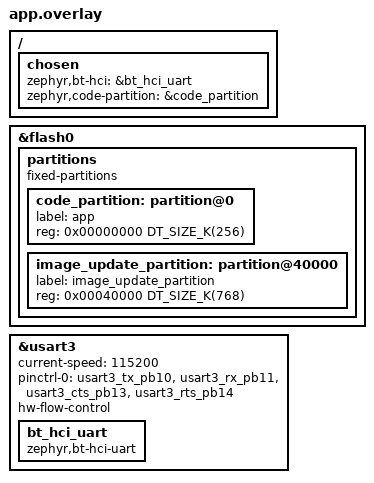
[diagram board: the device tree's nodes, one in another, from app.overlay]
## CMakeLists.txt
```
# SPDX-License-Identifier: Apache-2.0

cmake_minimum_required(VERSION 3.20.0)
set(BOARD stm32f4_disco)
find_package(Zephyr REQUIRED HINTS $ENV{ZEPHYR_BASE})
project(gateway)

include(${ZEPHYR_BASE}/samples/subsys/usb/common/common.cmake)
target_include_directories(app PRIVATE src/)
FILE(GLOB gateway_sources src/main.c 
                          src/command.c
                          src/external_firmware_update.c
                          
)
target_sources(app PRIVATE ${gateway_sources})
```

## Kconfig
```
# Copyright (c) 2023 Nordic Semiconductor ASA
# SPDX-License-Identifier: Apache-2.0

# Source common USB sample options used to initialize new experimental USB
# device stack. The scope of these options is limited to USB samples in project
# tree, you cannot use them in your own application.
# source "samples/subsys/usb/common/Kconfig.sample_usbd"

 source "Kconfig.zephyr"
```

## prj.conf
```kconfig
# enables the new gen usb stack
# CONFIG_USB_DEVICE_STACK_NEXT=y

# enables the console subsystem where the stdout will be redirected
CONFIG_STDOUT_CONSOLE=y

# enables serial/uart subsystem 
CONFIG_SERIAL=y

# for setting DTR, DSR, DCD, baud rate. uart_line_ctrl_get(dev, UART_LINE_CTRL_DTR, &dtr) which gives access to zephyr/drivers/uart.h
# important for 	k_msleep(100);
# CONFIG_UART_LINE_CTRL=y

# makes the cdc acm class instance not auto initialize (usbd_enable()), instead
# you do it manually in the code
# CONFIG_CDC_ACM_SERIAL_INITIALIZE_AT_BOOT=n

#enables log
CONFIG_LOG=y


CONFIG_LOG_MODE_IMMEDIATE=y

# limits log priority of usbd to err
# CONFIG_USBD_LOG_LEVEL_ERR=y

# Same idea, but for the UDC driver layer (the hardware controller driver itself) — errors only.
# CONFIG_UDC_DRIVER_LOG_LEVEL_ERR=y


# CONFIG_USBD_CDC_ACM_LOG_LEVEL_OFF=y
CONFIG_CONSOLE=y
CONFIG_UART_CONSOLE=y
CONFIG_WARN_EXPERIMENTAL=y
# CONFIG_SAMPLE_USBD_PID=0x0001
# CONFIG_SAMPLE_USBD_PRODUCT="USBD CDC ACM sample"

CONFIG_GPIO=y

# bluetooth hci uart setup
CONFIG_BT=y

# Directs Zephyr to route HCI packets over the physical UART peripheral 
# selected by your 'zephyr,bt-hci' chosen property in the device tree
# cna't configure it CONFIG_BT_UART=y


CONFIG_BT_H4=y

CONFIG_MAIN_STACK_SIZE=2048
CONFIG_SYSTEM_WORKQUEUE_STACK_SIZE=2048
CONFIG_BT_RX_STACK_SIZE=2048
# Allocates the background thread stack size for handling outgoing HCI packets
CONFIG_BT_HCI_TX_STACK_SIZE=1024



CONFIG_BT_HCI=y
CONFIG_BT_LL_SW_SPLIT=n #unsure
CONFIG_BT_DEVICE_NAME="gateway"

# central config
CONFIG_BT_CENTRAL=y
CONFIG_BT_SMP=y
CONFIG_BT_GATT_CLIENT=y
CONFIG_BT_HCI_ACL_FLOW_CONTROL=n

#CONFIG_BT_CTLR=n


CONFIG_UART_INTERRUPT_DRIVEN=y


CONFIG_FLASH_MAP=y
CONFIG_FLASH=y


CONFIG_BT_L2CAP_TX_MTU=247
CONFIG_BT_BUF_ACL_RX_SIZE=251
CONFIG_BT_GATT_CLIENT=y

#CONFIG_BT_CONN_TX_MAX=10
CONFIG_BT_BUF_ACL_TX_COUNT=10
CONFIG_BT_BUF_EVT_RX_COUNT=11
#CONFIG_BT_BUF_ACL_RX_COUNT_EXTRA=8
```

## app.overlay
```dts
/*
 * Copyright (c) 2021 Nordic Semiconductor ASA
 *
 * SPDX-License-Identifier: Apache-2.0
 */
/*
&zephyr_udc0 {
	cdc_acm_uart0: cdc_acm_uart0 {
		compatible = "zephyr,cdc-acm-uart";
		label = "Zephyr USB CDC-ACM";
	};
};
*/


// separating flash0 into partitions

&flash0 {
    partitions {
        compatible = "fixed-partitions";
        #address-cells = <1>;
        #size-cells = <1>;

        code_partition: partition@0 {
            label = "app";
            reg = <0x00000000 DT_SIZE_K(256)>;
        };

        image_update_partition: partition@40000 {
            label = "image_update_partition";
            reg = <0x00040000 DT_SIZE_K(768)>;
        };
    };
};





&usart3 {
    status = "okay";
    current-speed = <115200>;

    pinctrl-0 = <&usart3_tx_pb10 &usart3_rx_pb11 &usart3_cts_pb13 &usart3_rts_pb14>;
    pinctrl-names = "default";
	hw-flow-control;

    bt_hci_uart: bt_hci_uart {
        compatible = "zephyr,bt-hci-uart";
        status = "okay";
    };
};

/ {
    chosen {
        //zephyr,console = &cdc_acm_uart0;
//		zephyr,shell-uart= &cdc_acm_uart0;
		zephyr,bt-hci = &bt_hci_uart;
        zephyr,code-partition = &code_partition;

    };
};
```

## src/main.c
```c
/*
 * Copyright (c) 2019 Intel Corporation
 *
 * SPDX-License-Identifier: Apache-2.0
 */

#include <zephyr/types.h>
#include <stddef.h>
#include <errno.h>
#include <zephyr/kernel.h>
#include <zephyr/sys/printk.h>

#include <zephyr/bluetooth/bluetooth.h>
#include <zephyr/bluetooth/hci.h>
#include <zephyr/bluetooth/conn.h>
#include <zephyr/bluetooth/uuid.h>
#include <zephyr/bluetooth/gatt.h>
#include <zephyr/sys/byteorder.h>
#include <command.h>
#include <external_firmware_update.h>
// LOG_MODULE_REGISTER(main_log, LOG_LEVEL_INF);
static int start_scan(void);


#define DEVICE_NAME CONFIG_BT_DEVICE_NAME
#define DEVICE_NAME_LEN (sizeof(DEVICE_NAME) - 1)


/* Target service :*/
#define BT_UUID_CUSTOM_SERVICE_VAL \
	BT_UUID_128_ENCODE(0x12345678, 0x1234, 0x5678, 0x1234, 0x56789abcdef0)

static const struct bt_uuid_128 vnd_uuid = BT_UUID_INIT_128(
	BT_UUID_CUSTOM_SERVICE_VAL);

// sensor notification -------------------------------------------------------->
static const struct bt_uuid_128 vnd_sensor_uuid = BT_UUID_INIT_128(
BT_UUID_128_ENCODE(0x12345678, 0x1234, 0x5678, 0x1234, 0x56789abcdef5));




// message -------------------------------------------------------->
// message characteristic 
static const struct bt_uuid_128 vnd_msg_uuid = BT_UUID_INIT_128(
	BT_UUID_128_ENCODE(0x12345678, 0x1234, 0x5678, 0x1234, 0x56789abcdef6));

const struct bt_uuid_128 vnd_cmd_uuid = BT_UUID_INIT_128(
	BT_UUID_128_ENCODE(0x12345678, 0x1234, 0x5678, 0x1234, 0x56789abcdef7));

static const struct bt_uuid_128 vnd_cmd_feedback_uuid = BT_UUID_INIT_128(
BT_UUID_128_ENCODE(0x12345678, 0x1234, 0x5678, 0x1234, 0x56789abcdef8));

static const struct bt_uuid_128 vnd_payload_size_uuid = BT_UUID_INIT_128(
BT_UUID_128_ENCODE(0x12345678, 0x1234, 0x5678, 0x1234, 0x56789abcdef9));


static const struct bt_uuid_128 vnd_payload_chunk_uuid = BT_UUID_INIT_128(
BT_UUID_128_ENCODE(0x12345678, 0x1234, 0x5678, 0x1234, 0x56789abcdef10));

static const struct bt_uuid_128 vnd_payload_chunk_feedback_uuid = BT_UUID_INIT_128(
BT_UUID_128_ENCODE(0x12345678, 0x1234, 0x5678, 0x1234, 0x56789abcdef11));





#define MSG_MAX_LEN 32
char msg[MSG_MAX_LEN + 1] = {0};
uint16_t msg_attr_handle;
void msg_write_cb(struct bt_conn *conn, uint8_t err, struct bt_gatt_write_params *params){
	printf("a msg write request was sent!\n");
}
struct bt_gatt_write_params msg_write_params = {
	.func = msg_write_cb,
	.data = msg,
	.offset = 0,
	.length = MSG_MAX_LEN 
	
};
bool msg_ready = false;
// message -------------------------------------------------------->




struct bt_conn *default_conn;

uint64_t total_rx_count; /* This value is exposed to test code */
static struct bt_uuid_128 discover_uuid = BT_UUID_INIT_128(0);
static struct bt_gatt_discover_params discover_params;
static struct bt_gatt_subscribe_params subscribe_params;


static uint8_t notify_func(struct bt_conn *conn,
			   struct bt_gatt_subscribe_params *params,
			   const void *data, uint16_t length)
{
	if (!data) {
		printk("[UNSUBSCRIBED]\n");
		params->value_handle = 0U;
		return BT_GATT_ITER_STOP;
	}

	printk("[NOTIFICATION] data %p length %u\n", data, length);

	if (length == sizeof(int16_t)) {
		int16_t sensor_value;

		memcpy(&sensor_value, data, sizeof(sensor_value));
		sensor_value = sys_le16_to_cpu(sensor_value);

		printk("[NOTIFICATION] sensor value: %d\n", sensor_value);
	} else {
		printk("[NOTIFICATION] unexpected length %u\n", length);
	}
	total_rx_count++;

	return BT_GATT_ITER_CONTINUE;
}

enum subscribe_target {
    SUBSCRIBE_TARGET_NONE,
    SUBSCRIBE_TARGET_SENSOR,
    SUBSCRIBE_TARGET_CMD_FEEDBACK,
	SUBSCRIBE_TARGET_PAYLOAD_CHUNK_FEEDBACK,
};
static enum subscribe_target pending_subscribe_target = SUBSCRIBE_TARGET_NONE;

bool discovery_complete = false;
static uint8_t discover_func(struct bt_conn *conn,
			     const struct bt_gatt_attr *attr,
			     struct bt_gatt_discover_params *params)
{
	int err;

	if (!attr) {
		printk("Discover complete\n");
		(void)memset(params, 0, sizeof(*params));
		return BT_GATT_ITER_STOP;
	}

	printk("[ATTRIBUTE] handle %u\n", attr->handle);

	if (!bt_uuid_cmp(discover_params.uuid, &vnd_uuid.uuid)) {

		memcpy(&discover_uuid, &vnd_sensor_uuid, sizeof(discover_uuid));
		discover_params.uuid = &discover_uuid.uuid;
		discover_params.start_handle = attr->handle + 1;
		discover_params.type = BT_GATT_DISCOVER_CHARACTERISTIC;

		err = bt_gatt_discover(conn, &discover_params);
		if (err) {
			printk("Discover failed (err %d)\n", err);
		}

	} else if (!bt_uuid_cmp(discover_params.uuid,
				&vnd_msg_uuid.uuid)) {
		//memcpy(&discover_uuid, BT_UUID_GATT_CCC, sizeof(struct bt_uuid_16));
		//discover_params.uuid = &discover_uuid.uuid;
		//discover_params.start_handle = attr->handle + 2;
		//discover_params.type = BT_GATT_DISCOVER_DESCRIPTOR;

		msg_attr_handle = bt_gatt_attr_value_handle(attr);
		msg_write_params.handle = msg_attr_handle;
		msg_ready = true;


		// discover cmd
		memcpy(&discover_uuid, &vnd_cmd_uuid, sizeof(discover_uuid));
		discover_params.uuid = &discover_uuid.uuid;
		discover_params.start_handle = BT_ATT_FIRST_ATTRIBUTE_HANDLE;
		discover_params.type = BT_GATT_DISCOVER_CHARACTERISTIC;

		err = bt_gatt_discover(conn, &discover_params);
		if (err) {
			printk("Discover failed (err %d)\n", err);
		}
	 
		// cmd
	}  else if (!bt_uuid_cmp(discover_params.uuid,
				&vnd_cmd_uuid.uuid)) {

		 
		cmd_write_params.handle = bt_gatt_attr_value_handle(attr);
		
		// redirect to cmd_feedback
		memcpy(&discover_uuid, &vnd_cmd_feedback_uuid, sizeof(discover_uuid));
		discover_params.uuid = &discover_uuid.uuid;
		discover_params.start_handle = BT_ATT_FIRST_ATTRIBUTE_HANDLE;
		discover_params.type = BT_GATT_DISCOVER_CHARACTERISTIC;

		err = bt_gatt_discover(conn, &discover_params);
		if (err) {
			printk("Discover failed (err %d)\n", err);
		}

		// cmd_feedback
	}  else if (!bt_uuid_cmp(discover_params.uuid,
				&vnd_cmd_feedback_uuid.uuid)) {

		memcpy(&discover_uuid, BT_UUID_GATT_CCC, sizeof(struct bt_uuid_16));
		discover_params.uuid = &discover_uuid.uuid;
		discover_params.start_handle = attr->handle + 2;
		discover_params.type = BT_GATT_DISCOVER_DESCRIPTOR;
		cmd_feedback_subscribe_params.value_handle = bt_gatt_attr_value_handle(attr);

		pending_subscribe_target = SUBSCRIBE_TARGET_CMD_FEEDBACK;
		err = bt_gatt_discover(conn, &discover_params);
		if (err) {
			printk("Discover failed (err %d)\n", err);
		}
		// sensor
	}	else if (!bt_uuid_cmp(discover_params.uuid,
				&vnd_sensor_uuid.uuid)) {
		memcpy(&discover_uuid, BT_UUID_GATT_CCC, sizeof(struct bt_uuid_16));
		discover_params.uuid = &discover_uuid.uuid;
		discover_params.start_handle = attr->handle + 2;
		discover_params.type = BT_GATT_DISCOVER_DESCRIPTOR;
		subscribe_params.value_handle = bt_gatt_attr_value_handle(attr);

		pending_subscribe_target = SUBSCRIBE_TARGET_SENSOR; 
		err = bt_gatt_discover(conn, &discover_params);
		if (err) {
			printk("Discover failed (err %d)\n", err);
		}

	// discovering payloady_size
	}  else if (!bt_uuid_cmp(discover_params.uuid,
				&vnd_payload_size_uuid.uuid)) {

		 
			payload_size_write_params.handle = bt_gatt_attr_value_handle(attr);

			// redirecting to discover payload_chunk next
			memcpy(&discover_uuid, &vnd_payload_chunk_uuid, sizeof(discover_uuid));
			discover_params.uuid = &discover_uuid.uuid;
			discover_params.start_handle = BT_ATT_FIRST_ATTRIBUTE_HANDLE;
			discover_params.type = BT_GATT_DISCOVER_CHARACTERISTIC;

			err = bt_gatt_discover(conn, &discover_params);
			if (err) {
				printk("Discover failed (err %d)\n", err);

			}
		

	// discovering payloady_chunk
	}  else if (!bt_uuid_cmp(discover_params.uuid,
				&vnd_payload_chunk_uuid.uuid)) {

		 
		payload_chunk_write_params.handle = bt_gatt_attr_value_handle(attr);
		
		// redirect to payload_chunk_feedback 
		memcpy(&discover_uuid, &vnd_payload_chunk_feedback_uuid, sizeof(discover_uuid));
		discover_params.uuid = &discover_uuid.uuid;
		discover_params.start_handle = BT_ATT_FIRST_ATTRIBUTE_HANDLE;
		discover_params.type = BT_GATT_DISCOVER_CHARACTERISTIC;

		err = bt_gatt_discover(conn, &discover_params);
		if (err) {
			printk("Discover failed (err %d)\n", err);
		}

	// discovering payloady_chunk_feedback
	}  else if (!bt_uuid_cmp(discover_params.uuid,
				&vnd_payload_chunk_feedback_uuid.uuid)) {

		 
		
		memcpy(&discover_uuid, BT_UUID_GATT_CCC, sizeof(struct bt_uuid_16));
		discover_params.uuid = &discover_uuid.uuid;
		discover_params.start_handle = attr->handle + 2;
		discover_params.type = BT_GATT_DISCOVER_DESCRIPTOR;
		payload_chunk_feedback_subscribe_params.value_handle = bt_gatt_attr_value_handle(attr);

		pending_subscribe_target = SUBSCRIBE_TARGET_PAYLOAD_CHUNK_FEEDBACK;
		err = bt_gatt_discover(conn, &discover_params);
		if (err) {
			printk("Discover failed (err %d)\n", err);
		}
	} else //if 
	//(!bt_uuid_cmp(discover_params.uuid, BT_UUID_GATT_CCC.uuid)) 
	{
		if(pending_subscribe_target == SUBSCRIBE_TARGET_SENSOR){
			subscribe_params.notify = notify_func;
			subscribe_params.value = BT_GATT_CCC_NOTIFY;
			subscribe_params.ccc_handle = attr->handle;

			err = bt_gatt_subscribe(conn, &subscribe_params);
			if (err && err != -EALREADY) {
				printk("Subscribe failed (err %d)\n", err);
			} else {
				printk("[SUBSCRIBED] sensor notification\n");
			}

			memcpy(&discover_uuid, &vnd_msg_uuid, sizeof(discover_uuid));
			discover_params.uuid = &discover_uuid.uuid;
			discover_params.start_handle = BT_ATT_FIRST_ATTRIBUTE_HANDLE;
			discover_params.type = BT_GATT_DISCOVER_CHARACTERISTIC;

			err = bt_gatt_discover(conn, &discover_params);
			if (err) {
				printk("Discover failed (err %d)\n", err);

			}
		}
		else if(pending_subscribe_target == SUBSCRIBE_TARGET_CMD_FEEDBACK){
			cmd_feedback_subscribe_params.notify = cmd_feedback_notify_func;
			cmd_feedback_subscribe_params.value = BT_GATT_CCC_NOTIFY;
			cmd_feedback_subscribe_params.ccc_handle = attr->handle;

			err = bt_gatt_subscribe(conn, &cmd_feedback_subscribe_params);
			if (err && err != -EALREADY) {
				printk("Subscribe failed (err %d)\n", err);
			} else {
				printk("[SUBSCRIBED] to cmd feedback notification\n");
			}

			// redirecting to discover payloay_size next
			memcpy(&discover_uuid, &vnd_payload_size_uuid, sizeof(discover_uuid));
			discover_params.uuid = &discover_uuid.uuid;
			discover_params.start_handle = BT_ATT_FIRST_ATTRIBUTE_HANDLE;
			discover_params.type = BT_GATT_DISCOVER_CHARACTERISTIC;

			err = bt_gatt_discover(conn, &discover_params);
			if (err) {
				printk("Discover failed (err %d)\n", err);

			}

			
		}
		
		else if(pending_subscribe_target == SUBSCRIBE_TARGET_PAYLOAD_CHUNK_FEEDBACK){
			payload_chunk_feedback_subscribe_params.notify = payload_chunk_feedback_notify_func;
			payload_chunk_feedback_subscribe_params.value = BT_GATT_CCC_NOTIFY;
			payload_chunk_feedback_subscribe_params.ccc_handle = attr->handle;

			err = bt_gatt_subscribe(conn, &payload_chunk_feedback_subscribe_params);
			if (err && err != -EALREADY) {
				printk("Subscribe failed (err %d)\n", err);
			} else {
				printk("[SUBSCRIBED] to payload chunk feedback notification\n");
			}

			discovery_complete = true;
			
		}

	}

	return BT_GATT_ITER_STOP;
}

/*
static bool eir_found(struct bt_data *data, void *user_data)
{
	bt_addr_le_t *addr = user_data;
	int i;

	printk("[AD]: %u data_len %u\n", data->type, data->data_len);

	switch (data->type) {
	case BT_DATA_UUID128_SOME:
	case BT_DATA_UUID128_ALL:
		// check if we can fine a multiple of 16 bytes uuid (128 bits)
		if (data->data_len % 16 != 0U) {
			printk("AD malformed\n");
			return true;
		}

		for (i = 0; i < data->data_len; i += 16) {
			struct bt_conn_le_create_param *create_param;
			struct bt_le_conn_param *param;
			// const struct bt_uuid *uuid;
			// uint16_t u16;
			struct bt_uuid_128 uuid128;
			uuid128.uuid.type = BT_UUID_TYPE_128;
			int err;

			memcpy(&uuid128.val, &data->data[i], 16);
			// uuid = BT_UUID_DECLARE_16(sys_le16_to_cpu(u16));
			if (bt_uuid_cmp(&uuid128.uuid, &vnd_uuid.uuid)) {
				continue;
			}

			err = bt_le_scan_stop();
			if (err) {
				printk("Stop LE scan failed (err %d)\n", err);
				continue;
			}

			printk("Creating connection with Coded PHY support\n");
			param = BT_LE_CONN_PARAM_DEFAULT;
			create_param = BT_CONN_LE_CREATE_CONN;
			create_param->options |= BT_CONN_LE_OPT_CODED;
			err = bt_conn_le_create(addr, create_param, param,
						&default_conn);
			if (err) {
				printk("Create connection with Coded PHY support failed (err %d)\n",
				       err);

				printk("Creating non-Coded PHY connection\n");
				create_param->options &= ~BT_CONN_LE_OPT_CODED;
				err = bt_conn_le_create(addr, create_param,
							param, &default_conn);
				if (err) {
					printk("Create connection failed (err %d)\n", err);
					start_scan();
				}
			}

			return false;
		}
	}

	return true;
}
*/

static bool eir_found(struct bt_data *data, void *user_data)
{
    bt_addr_le_t *addr = user_data;
    int i;

    printk("[AD]: %u data_len %u\n", data->type, data->data_len);

    switch (data->type) {
    case BT_DATA_UUID128_SOME:
    case BT_DATA_UUID128_ALL:
        if (data->data_len % 16 != 0U) {
            printk("AD malformed\n");
            return true;
        }

        for (i = 0; i < data->data_len; i += 16) {
            struct bt_le_conn_param *param;
            struct bt_uuid_128 uuid128;
            uuid128.uuid.type = BT_UUID_TYPE_128;
            int err;

            memcpy(&uuid128.val, &data->data[i], 16);
            if (bt_uuid_cmp(&uuid128.uuid, &vnd_uuid.uuid)) {
                continue;
            }

            err = bt_le_scan_stop();
            if (err) {
                printk("Stop LE scan failed (err %d)\n", err);
                continue;
            }

            printk("Creating connection\n");
            param = BT_LE_CONN_PARAM_DEFAULT;
            err = bt_conn_le_create(addr, BT_CONN_LE_CREATE_CONN, param, &default_conn);
            if (err) {
                printk("Create connection failed (err %d)\n", err);
                start_scan();
            }

            return false;
        }
    }

    return true;
}

static void device_found(const bt_addr_le_t *addr, int8_t rssi, uint8_t type,
			 struct net_buf_simple *ad)
{
	printk("[DEVICE]: %s, AD evt type %u, AD data len %u, RSSI %i\n",
	       bt_addr_le_str(addr), type, ad->len, rssi);

	/* We're only interested in legacy connectable events or
	 * possible extended advertising that are connectable.
	 */
	if (type == BT_GAP_ADV_TYPE_ADV_IND ||
	    type == BT_GAP_ADV_TYPE_ADV_DIRECT_IND ||
	    type == BT_GAP_ADV_TYPE_EXT_ADV) {
		bt_data_parse(ad, eir_found, (void *)addr);
	}
}

static int start_scan(void)
{
	int err;

	/* Use active scanning and disable duplicate filtering to handle any
	 * devices that might update their advertising data at runtime. */
	struct bt_le_scan_param scan_param = {
		.type       = BT_LE_SCAN_TYPE_ACTIVE,
		.options    = BT_LE_SCAN_OPT_NONE,
		.interval   = BT_GAP_SCAN_FAST_INTERVAL,
		.window     = BT_GAP_SCAN_FAST_WINDOW,
	};

	err = bt_le_scan_start(&scan_param, device_found);
	if (err) {
		/*
		printk("Scanning with Coded PHY support failed (err %d)\n", err);

		printk("Scanning without Coded PHY\n");
		scan_param.options &= ~BT_LE_SCAN_OPT_CODED;
		err = bt_le_scan_start(&scan_param, device_found);
		if (err) {
			printk("Scanning failed to start (err %d)\n", err);
			return -1;
		}
		*/
	    printk("Scanning failed to start (err %d)\n", err);
        return -1;
	}

	printk("Scanning successfully started\n");
	return 0;
}

// 1. Declare the MTU exchange parameter struct
static struct bt_gatt_exchange_params mtu_params;

// 2. Define the callback function when the exchange finishes
static void mtu_exchange_cb(struct bt_conn *conn, uint8_t err,
			    struct bt_gatt_exchange_params *params)
{
	if (!err) {
		printk("MTU exchange successful\n");
	} else {
		printk("MTU exchange failed (err %d)\n", err);
	}
}


bool gateway_is_connected = false;

static void connected(struct bt_conn *conn, uint8_t conn_err)
{
	int err;

	if (conn_err) {
		printk("Failed to connect to %s (%u)\n", bt_conn_dst_str(conn), conn_err);

		bt_conn_drop(&default_conn);

		start_scan();
		return;
	}

	printk("Connected: %s\n", bt_conn_dst_str(conn));

	total_rx_count = 0U;

	if (conn == default_conn) {
		memcpy(&discover_uuid, &vnd_uuid.uuid, sizeof(discover_uuid));
		discover_params.uuid = &discover_uuid.uuid;
		discover_params.func = discover_func;
		discover_params.start_handle = BT_ATT_FIRST_ATTRIBUTE_HANDLE;
		discover_params.end_handle = BT_ATT_LAST_ATTRIBUTE_HANDLE;
		discover_params.type = BT_GATT_DISCOVER_PRIMARY;

		err = bt_gatt_discover(default_conn, &discover_params);
		if (err) {
			printk("Discover failed(err %d)\n", err);
			return;
		}
	}

	// Trigger the MTU exchange
	mtu_params.func = mtu_exchange_cb;
	int rc = bt_gatt_exchange_mtu(conn, &mtu_params);
	if (rc) {
		printk("MTU exchange failed to initiate (err %d)\n", rc);
	}
	printf("gateway is connect!\n");
	gateway_is_connected = true;
}


bool need_to_rescan = false;

static void disconnected(struct bt_conn *conn, uint8_t reason)
{
	gateway_is_connected = false;
	need_to_rescan = true;

	printk("Disconnected: %s, reason 0x%02x %s\n", bt_conn_dst_str(conn),
	       reason, bt_hci_err_to_str(reason));

	if (default_conn != conn) {
		return;
	}

	bt_conn_drop(&default_conn);
	discovery_complete = false;

	printf("Disconnected call baby \n");


}

BT_CONN_CB_DEFINE(conn_callbacks) = {
	.connected = connected,
	.disconnected = disconnected,
};


#include <zephyr/storage/flash_map.h>
int main(void)
{

	
	/*
	static const struct gpio_dt_spec led = GPIO_DT_SPEC_GET(DT_ALIAS(led0), gpios);
	gpio_pin_configure_dt(&led, GPIO_OUTPUT_ACTIVE);

	while (1) {
		gpio_pin_toggle_dt(&led);
		k_msleep(500);
	}
		*/
	int err;
	printf("running bluetooth\n");
	err = bt_enable(NULL);
    if (err) {
        printf("Bluetooth init failed (err %d)\n", err);
        return err;
    }
	start_scan();
	snprintk(msg, MSG_MAX_LEN, "hello");

	int start_firmware_update = 1;

	// main loop
	while(true){
		k_sleep(K_SECONDS(1));

		if(need_to_rescan){
			need_to_rescan = false;
			start_scan();
		}
		k_sleep(K_SECONDS(2));
		if(gateway_is_connected){
			if(msg_ready)	bt_gatt_write(default_conn, &msg_write_params);

			// initiating firmware update
			if(start_firmware_update){
				start_firmware_update = 0;
				cmd = UPDATE_CMD;
				bt_gatt_write(default_conn, &cmd_write_params);
				printf("sent cmd.\n");
				while(true){
					//printf("waiting for cmd feedback...\n");
					if(cmd_feedback == OTA_UPDATE_READY) {
						printf("received cmd feedback confirmation.\n");
						//consume flag
						cmd_feedback = NO_FEEDBACK;
						break;
					}
				}
				firmware_update();
				//gateway_is_connected = false;
				//bt_conn_disconnect(default_conn, BT_HCI_ERR_REMOTE_USER_TERM_CONN);
			}
		}	
		printf("Back to main loop baby\n");
	}
	
	return 0;
}
```

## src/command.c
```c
#include <command.h>

#include <stdint.h>
volatile uint8_t cmd_feedback = NO_FEEDBACK;
volatile uint8_t cmd = NO_CMD;
struct bt_gatt_subscribe_params cmd_feedback_subscribe_params;
void cmd_write_cb(struct bt_conn *conn, uint8_t err, struct bt_gatt_write_params *params){
	printf("a cmd write request was sent!\n");
}
struct bt_gatt_write_params cmd_write_params = {
	.func = cmd_write_cb,
	.data = &cmd,
	.offset = 0,
	.length = sizeof(cmd) 
	
};
extern uint64_t total_rx_count;
uint8_t cmd_feedback_notify_func(struct bt_conn *conn,
			   struct bt_gatt_subscribe_params *params,
			   const void *data, uint16_t length)
{
	if (!data) {
		printk("[UNSUBSCRIBED]\n");
		params->value_handle = 0U;
		return BT_GATT_ITER_STOP;
	}

	printk("[NOTIFICATION] data %p length %u\n", data, length);
    printk("this is the feedback notification :)\n");

	if (length == sizeof(cmd_feedback)) {
		uint8_t cmd_feedback_value;

		memcpy(&cmd_feedback_value, data, sizeof(cmd_feedback_value));
        cmd_feedback = cmd_feedback_value;
		printk("[NOTIFICATION] cmd feedback value: %d\n", cmd_feedback_value);
	} else {
		printk("[NOTIFICATION] unexpected length %u\n", length);
	}
	total_rx_count++;

	return BT_GATT_ITER_CONTINUE;
}
```

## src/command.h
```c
#ifndef COMMAND_H
#define COMMAND_H
#include <stdint.h>
#include <zephyr/bluetooth/bluetooth.h>
#include <zephyr/bluetooth/hci.h>
#include <zephyr/bluetooth/conn.h>
#include <zephyr/bluetooth/uuid.h>
#include <zephyr/bluetooth/gatt.h>
#include <zephyr/sys/byteorder.h>
enum Commands{
	NO_CMD = 0,
	UPDATE_CMD = 1,
};

enum CmdFeedbacks{
	NO_FEEDBACK = 0,
	OTA_UPDATE_READY = 1,
	OTA_UPDATE_NOT_READY = 2,
};
extern volatile uint8_t cmd_feedback ;
extern volatile uint8_t cmd;
extern struct bt_gatt_write_params cmd_write_params;
extern struct bt_gatt_subscribe_params cmd_feedback_subscribe_params;
void cmd_write_cb(struct bt_conn *conn, uint8_t err, struct bt_gatt_write_params *params);
uint8_t cmd_feedback_notify_func(struct bt_conn *conn,
			   struct bt_gatt_subscribe_params *params,
			   const void *data, uint16_t length);
#endif
```

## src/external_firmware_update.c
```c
#include <external_firmware_update.h>

LOG_MODULE_REGISTER(external_firmware_update, LOG_LEVEL_INF);


static int32_t payload_size;

static void payload_size_write_cb(struct bt_conn *conn, uint8_t err, struct bt_gatt_write_params *params){
    // add proper error handling with err
    LOG_INF("payload size has been written.\n");
}

struct bt_gatt_write_params payload_size_write_params = {
	.func = payload_size_write_cb,
	.data = &payload_size,
	.offset = 0,
	.length = sizeof(payload_size) 
	
};
void send_payload_size(int32_t payload_size_param){
    // ADD value checks
    payload_size = payload_size_param;
	bt_gatt_write(default_conn, &payload_size_write_params);
}




// sending payload chunk


#define CHUNK_DATA_SIZE 239
struct PayloadChunk
{
	int32_t index;
	char data[CHUNK_DATA_SIZE];
	uint8_t len;
} __packed;

static struct PayloadChunk payload_chunk;
K_SEM_DEFINE(payload_write_done, 0, 1);
static void payload_chunk_write_cb(struct bt_conn *conn, uint8_t err, struct bt_gatt_write_params *params){
    // add proper error handling with err
    LOG_INF("payload chunk has been written.\n");
    k_sem_give(&payload_write_done);
}

struct bt_gatt_write_params payload_chunk_write_params = {
	.func = payload_chunk_write_cb,
	.data = &payload_chunk,
	.offset = 0,
	.length = sizeof(payload_chunk) 
	
};
void send_payload_chunk(struct PayloadChunk pc){
    // ADD value checks
    // TODO: make sure that all values are reasonable
    payload_chunk = pc;
	bt_gatt_write(default_conn, &payload_chunk_write_params);
    k_sem_take(&payload_write_done, K_FOREVER);
}




enum PayloadChunkFeedback{
	NO_FEEDBACK = 0,
	CHUNK_MISSED = 1,
	CHUNK_ACCEPTED = 2,
};
static uint8_t payload_chunk_feedback = NO_FEEDBACK;

struct bt_gatt_subscribe_params payload_chunk_feedback_subscribe_params;


// setting up the payload chunk feedback semaphore chunk
K_SEM_DEFINE(payload_chunk_feedback_flag, 0, 1);

//TODO: Include total rx count?
uint8_t payload_chunk_feedback_notify_func(struct bt_conn *conn,
			   struct bt_gatt_subscribe_params *params,
			   const void *data, uint16_t length)
{
	if (!data) {
		printk("[UNSUBSCRIBED]\n");
		params->value_handle = 0U;
		return BT_GATT_ITER_STOP;
	}

	printf("[NOTIFICATION] data %p length %u\n", data, length);
    printf("this is the payload chunk feedback notification :)\n");

	if (length == sizeof(payload_chunk_feedback)) {
		uint8_t payload_chunk_feedback_value;

		memcpy(&payload_chunk_feedback_value, data, sizeof(payload_chunk_feedback_value));
        payload_chunk_feedback = payload_chunk_feedback_value;
		printk("[NOTIFICATION] payload chunk feedback value: %d\n", payload_chunk_feedback_value);
	} else {
		printk("[NOTIFICATION] unexpected length %u\n", length);
	}
	//total_rx_count++;

    k_sem_give(&payload_chunk_feedback_flag);

	return BT_GATT_ITER_CONTINUE;
}

int start_firmware_update = 1;

void firmware_update(){
    
    const struct flash_area* image_update_partition;
    int err = flash_area_open(PARTITION_ID(image_update_partition), &image_update_partition);

    if (err)
    {
        printf("failed to open image_update_partition\n");
        return ;
    }
    else
    {
        printf("image_update_partition is open.\n");
    }

    size_t image_size = PARTITION_SIZE(image_update_partition);
    //size_t image_size = 50000;
    send_payload_size(image_size);

    // Setup
    int32_t chunks_count = image_size / CHUNK_DATA_SIZE + ((image_size % CHUNK_DATA_SIZE ) == 0 ? 0 : 1);
    int32_t chunk_index = 0;
    bool finished_last_chunk = false;
    while(chunk_index < chunks_count){
        if(chunk_index % 40 == 0) k_msleep(500);
        printf("Attempting external firmware update loop with index: %d\n", chunk_index);
        if(chunk_index == chunks_count -1) finished_last_chunk = true;
       struct PayloadChunk pc;
       pc.index = chunk_index;
       if(chunk_index == chunks_count - 1 && (image_size % CHUNK_DATA_SIZE ) != 0){
            pc.len =  image_size % CHUNK_DATA_SIZE;
       } 
       else{
            pc.len = CHUNK_DATA_SIZE;
       }
       flash_area_read(image_update_partition, chunk_index * CHUNK_DATA_SIZE, pc.data, pc.len);
       send_payload_chunk(pc);
       printf("Waiting for the semaphore to release\n");
       k_sem_take(&payload_chunk_feedback_flag, K_FOREVER);
       printf("The semaphore has release\n");
       if(payload_chunk_feedback == CHUNK_ACCEPTED){
        chunk_index++;
       } else if(payload_chunk_feedback == CHUNK_MISSED){
        // repeat the same chunk
       } else {
        printf("unknow payload chunk feedback\n");
       }
       
	   if(finished_last_chunk) break;
    }

    flash_area_close(image_update_partition);

	printf("External firmware update is done.\n");
}
```

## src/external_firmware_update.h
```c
#ifndef EXTERNAL_FIRMWARE_UPDATE_H
#define EXTERNAL_FIRMWARE_UPDATE_H
#include <stdio.h>
#include <zephyr/dfu/mcuboot.h>
#include <zephyr/toolchain.h>
#include <zephyr/kernel.h>
#include <zephyr/sys/reboot.h>
#include <zephyr/logging/log.h>
#include <zephyr/storage/flash_map.h>
#include <zephyr/bluetooth/gatt.h>
#include <stdio.h>
#include <main.h>
#include <zephyr/kernel.h>
extern int start_firmware_update;
void firmware_update();
extern struct bt_gatt_write_params payload_size_write_params; 
void send_payload_size(int32_t payload_size_param);
extern struct bt_gatt_write_params payload_chunk_write_params;
extern struct bt_gatt_subscribe_params payload_chunk_feedback_subscribe_params;
uint8_t payload_chunk_feedback_notify_func(struct bt_conn *conn,
			   struct bt_gatt_subscribe_params *params,
			   const void *data, uint16_t length);
#endif
```

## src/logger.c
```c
#include <logger.h>


LOG_MODULE_REGISTER(gateway_log, LOG_LEVEL_INF);

const struct device *const uart_dev = DEVICE_DT_GET_ONE(zephyr_cdc_acm_uart);

#define RING_BUF_SIZE 1024
uint8_t ring_buffer[RING_BUF_SIZE];

struct ring_buf ringbuf;

static bool rx_throttled;

static inline void print_baudrate(const struct device *dev)
{
	uint32_t baudrate;
	int ret;

	ret = uart_line_ctrl_get(dev, UART_LINE_CTRL_BAUD_RATE, &baudrate);
	if (ret) {
		LOG_WRN("Failed to get baudrate, ret code %d", ret);
	} else {
		LOG_INF("Baudrate %u", baudrate);
	}
}

static struct usbd_context *sample_usbd;
K_SEM_DEFINE(dtr_sem, 0, 1);

static void sample_msg_cb(struct usbd_context *const ctx, const struct usbd_msg *msg)
{
	LOG_INF("USBD message: %s", usbd_msg_type_string(msg->type));

	if (usbd_can_detect_vbus(ctx)) {
		if (msg->type == USBD_MSG_VBUS_READY) {
			if (usbd_enable(ctx)) {
				LOG_ERR("Failed to enable device support");
			}
		}

		if (msg->type == USBD_MSG_VBUS_REMOVED) {
			if (usbd_disable(ctx)) {
				LOG_ERR("Failed to disable device support");
			}
		}
	}

	if (msg->type == USBD_MSG_CDC_ACM_CONTROL_LINE_STATE) {
		uint32_t dtr = 0U;

		uart_line_ctrl_get(msg->dev, UART_LINE_CTRL_DTR, &dtr);
		if (dtr) {
			k_sem_give(&dtr_sem);
		}
	}

	if (msg->type == USBD_MSG_CDC_ACM_LINE_CODING) {
		print_baudrate(msg->dev);
	}
}

static int enable_usb_device_next(void)
{
	int err;

	sample_usbd = sample_usbd_init_device(sample_msg_cb);
	if (sample_usbd == NULL) {
		LOG_ERR("Failed to initialize USB device");
		return -ENODEV;
	}

	if (!usbd_can_detect_vbus(sample_usbd)) {
		err = usbd_enable(sample_usbd);
		if (err) {
			LOG_ERR("Failed to enable device support");
			return err;
		}
	}

	LOG_INF("USB device support enabled");

	return 0;
}

/*

static void interrupt_handler(const struct device *dev, void *user_data)
{
	ARG_UNUSED(user_data);

	while (true) {
		uart_irq_update(dev);

		if (uart_irq_is_pending(dev) <= 0) {
			break;
		}

		if (!rx_throttled && uart_irq_rx_ready(dev)) {
			int recv_len, rb_len;
			uint8_t buffer[64];
			size_t len = MIN(ring_buf_space_get(&ringbuf),
					 sizeof(buffer));

			if (len == 0) {
				// Throttle because ring buffer is full 
				uart_irq_rx_disable(dev);
				rx_throttled = true;
				continue;
			}

			recv_len = uart_fifo_read(dev, buffer, len);
			if (recv_len < 0) {
				LOG_ERR("Failed to read UART FIFO");
				recv_len = 0;
			};

			rb_len = ring_buf_put(&ringbuf, buffer, recv_len);
			if (rb_len < recv_len) {
				LOG_ERR("Drop %u bytes", recv_len - rb_len);
			}

			LOG_DBG("tty fifo -> ringbuf %d bytes", rb_len);
			if (rb_len) {
				uart_irq_tx_enable(dev);
			}
		}

		if (uart_irq_tx_ready(dev)) {
			uint8_t buffer[64];
			int rb_len, send_len;

			rb_len = ring_buf_get(&ringbuf, buffer, sizeof(buffer));
			if (!rb_len) {
				LOG_DBG("Ring buffer empty, disable TX IRQ");
				uart_irq_tx_disable(dev);
				continue;
			}

			if (rx_throttled) {
				uart_irq_rx_enable(dev);
				rx_throttled = false;
			}

			send_len = uart_fifo_fill(dev, buffer, rb_len);
			if (send_len < rb_len) {
				LOG_ERR("Drop %d bytes", rb_len - send_len);
			}

			LOG_DBG("ringbuf -> tty fifo %d bytes", send_len);
		}
	}
}
*/

void init_logging(){

	int ret;

	if (!device_is_ready(uart_dev)) {
		LOG_ERR("CDC ACM device not ready");
		return ;
	}

	ret = enable_usb_device_next();
	if (ret != 0) {
		LOG_ERR("Failed to enable USB device support");
		return ;
	}

	ring_buf_init(&ringbuf, sizeof(ring_buffer), ring_buffer);

	LOG_INF("Wait for DTR");
	k_sem_take(&dtr_sem, K_FOREVER);
	LOG_INF("DTR set");

	/* They are optional, we use them to test the interrupt endpoint */
/*	ret = uart_line_ctrl_set(uart_dev, UART_LINE_CTRL_DCD, 1);
	if (ret) {
		LOG_WRN("Failed to set DCD, ret code %d", ret);
	}

	ret = uart_line_ctrl_set(uart_dev, UART_LINE_CTRL_DSR, 1);
	if (ret) {
		LOG_WRN("Failed to set DSR, ret code %d", ret);
	}
*/


//	uart_irq_callback_set(uart_dev, interrupt_handler);
	/* Enable rx interrupts */
//	uart_irq_rx_enable(uart_dev);
}
```

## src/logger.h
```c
#ifndef LOGGER_H
#define LOGGER_H

#include <sample_usbd.h>
#include <stdio.h>
#include <string.h>
#include <zephyr/device.h>
#include <zephyr/drivers/uart.h>
#include <zephyr/kernel.h>
#include <zephyr/sys/ring_buffer.h>

#include <zephyr/usb/usbd.h>
#include <zephyr/logging/log.h>
void init_logging();

#endif
```

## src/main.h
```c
#ifndef MAIN_H
#define MAIN_H
extern struct bt_conn *default_conn;
#endif
```
